# R7FA6M5BH register map
Vendor: Renesas Electronics Corporation; Series: RA6; File version: 1.20.01
CPU: CM33 r0p4, little endian, MPU, FPU, VTOR, 4 interrupt priority bits, 96 interrupts
Registers are 32-bit, read-write, reset 0x0 unless marked. A register's access mark holds for its fields unless they carry their own. Offsets are from the block's base; [hi:lo] are bit positions; {n}, {i} and the like mark numbered series; 'fields as' and 'values as' point back to an identical list.

## PFS — Control Register
Base 0x40080800
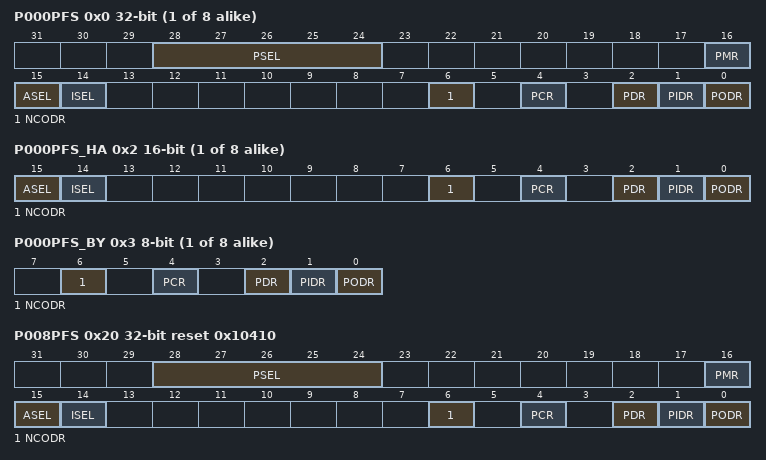
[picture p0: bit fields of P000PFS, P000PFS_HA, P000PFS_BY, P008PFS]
{0x0+4i} P00{i}PFS (i=0..7) (reset mask 0xFFFFFFFD) — Port 00{i} Pin Function Select Register
  [28:24] PSEL — Peripheral Select
  [16] PMR — Port Mode Control
    0=Use as general I/O pin; 1=Use as I/O port for peripheral functions
  [15] ASEL — Analog Input Enable
    0=Do not use as analog pin; 1=Use as analog pin
  [14] ISEL — IRQ Input Enable
    0=Do not use as IRQn input pin; 1=Use as IRQn input pin
  [6] NCODR — N-Channel Open-Drain Control
    0=Output CMOS; 1=Output NMOS open-drain
  [4] PCR — Pull-up Control
    0=Disable input pull-up; 1=Enable input pull-up
  [2] PDR — Port Direction
    0=Input (functions as an input pin); 1=Output (functions as an output pin)
  [1] PIDR ro — Port State
    0=Low level; 1=High level
  [0] PODR — Port Output Data
    0=Output low; 1=Output high
{0x2+4i} P00{i}PFS_HA (i=0..7) 16-bit (reset mask 0xFFFD) (alternate view of P00{i}PFS) — Port 00{i} Pin Function Select Register
  [15] ASEL — Analog Input Enable
    0=Do not use as analog pin; 1=Use as analog pin
  [14] ISEL — IRQ Input Enable
    0=Do not use as IRQn input pin; 1=Use as IRQn input pin
  [6] NCODR — N-Channel Open-Drain Control
    0=Output CMOS; 1=Output NMOS open-drain
  [4] PCR — Pull-up Control
    0=Disable input pull-up; 1=Enable input pull-up
  [2] PDR — Port Direction
    values as P000PFS.PDR
  [1] PIDR ro — Port State
    0=Low level; 1=High level
  [0] PODR — Port Output Data
    0=Output low; 1=Output high
{0x3+4i} P00{i}PFS_BY (i=0..7) 8-bit (reset mask 0xFD) (alternate view of P00{i}PFS) — Port 00{i} Pin Function Select Register
  [6] NCODR — N-Channel Open-Drain Control
    0=Output CMOS; 1=Output NMOS open-drain
  [4] PCR — Pull-up Control
    0=Disable input pull-up; 1=Enable input pull-up
  [2] PDR — Port Direction
    values as P000PFS.PDR
  [1] PIDR ro — Port State
    0=Low level; 1=High level
  [0] PODR — Port Output Data
    0=Output low; 1=Output high
0x20 P008PFS reset 0x10410 (reset mask 0xFFFFFFFD) — Port 008 Pin Function Select Register
  fields as P000PFS
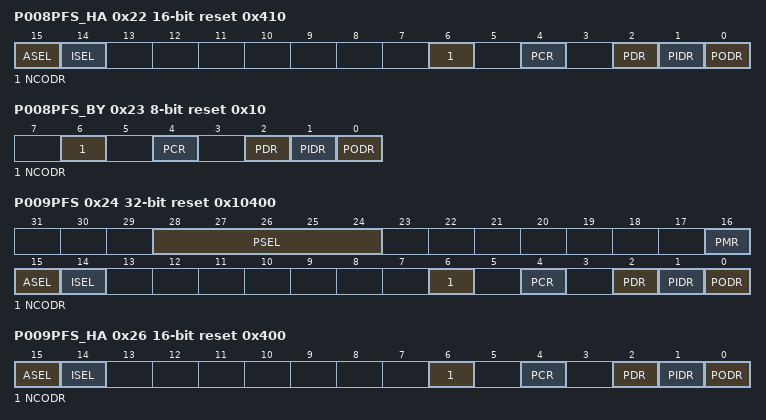
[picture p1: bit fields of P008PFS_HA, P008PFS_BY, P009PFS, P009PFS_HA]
0x22 P008PFS_HA 16-bit reset 0x410 (reset mask 0xFFFD) (alternate view of P008PFS) — Port 008 Pin Function Select Register
  fields as P000PFS_HA
0x23 P008PFS_BY 8-bit reset 0x10 (reset mask 0xFD) (alternate view of P008PFS) — Port 008 Pin Function Select Register
  fields as P000PFS_BY
0x24 P009PFS reset 0x10400 (reset mask 0xFFFFFFFD) — Port 009 Pin Function Select Register
  fields as P000PFS
0x26 P009PFS_HA 16-bit reset 0x400 (reset mask 0xFFFD) (alternate view of P009PFS) — Port 009 Pin Function Select Register
  fields as P000PFS_HA
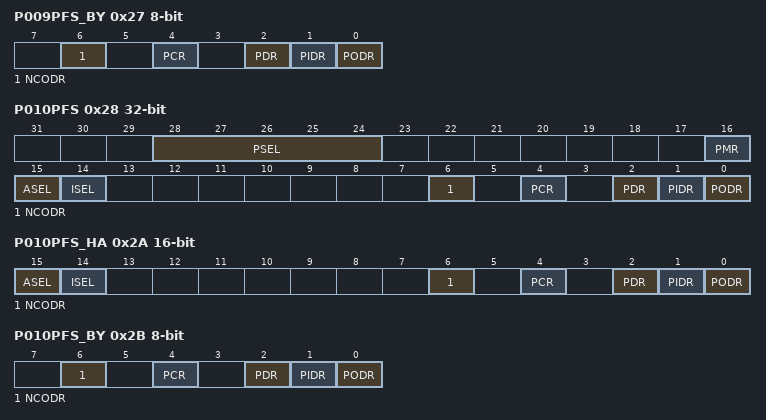
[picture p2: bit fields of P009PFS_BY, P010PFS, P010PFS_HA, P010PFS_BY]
0x27 P009PFS_BY 8-bit (reset mask 0xFD) (alternate view of P009PFS) — Port 009 Pin Function Select Register
  fields as P000PFS_BY
0x28 P010PFS (reset mask 0xFFFFFFFD) — Port 010 Pin Function Select Register
  fields as P000PFS
0x2A P010PFS_HA 16-bit (reset mask 0xFFFD) (alternate view of P010PFS) — Port 010 Pin Function Select Register
  fields as P000PFS_HA
0x2B P010PFS_BY 8-bit (reset mask 0xFD) (alternate view of P010PFS) — Port 010 Pin Function Select Register
  fields as P000PFS_BY
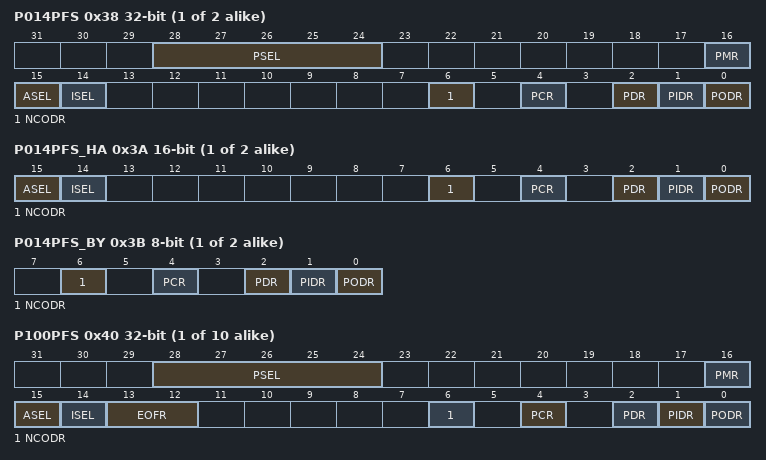
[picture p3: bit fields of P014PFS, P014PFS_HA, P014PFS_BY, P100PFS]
{0x0+4i} P0{i}PFS (i=14..15) (reset mask 0xFFFFFFFD) — Port 0{i} Pin Function Select Register
  fields as P000PFS
{0x2+4i} P0{i}PFS_HA (i=14..15) 16-bit (reset mask 0xFFFD) (alternate view of P0{i}PFS) — Port 0{i} Pin Function Select Register
  fields as P000PFS_HA
{0x3+4i} P0{i}PFS_BY (i=14..15) 8-bit (reset mask 0xFD) (alternate view of P0{i}PFS) — Port 0{i} Pin Function Select Register
  fields as P000PFS_BY
{0x40+4i} P10{i}PFS (i=0..9) (reset mask 0xFFFFFFFD) — Port 10{i} Pin Function Select Register
  [28:24] PSEL — Peripheral Select
  [16] PMR — Port Mode Control
    values as P000PFS.PMR
  [15] ASEL — Analog Input Enable
    0=Do not use as analog pin; 1=Use as analog pin
  [14] ISEL — IRQ Input Enable
    0=Do not use as IRQn input pin; 1=Use as IRQn input pin
  [13:12] EOFR — Event on Falling/Event on Rising
    0=Don't care; 1=Detect rising edge; 2=Detect falling edge; 3=Detect both edges
  [6] NCODR — N-Channel Open-Drain Control
    0=Output CMOS; 1=Output NMOS open-drain
  [4] PCR — Pull-up Control
    0=Disable input pull-up; 1=Enable input pull-up
  [2] PDR — Port Direction
    values as P000PFS.PDR
  [1] PIDR ro — Port State
    0=Low level; 1=High level
  [0] PODR — Port Output Data
    0=Output low; 1=Output high
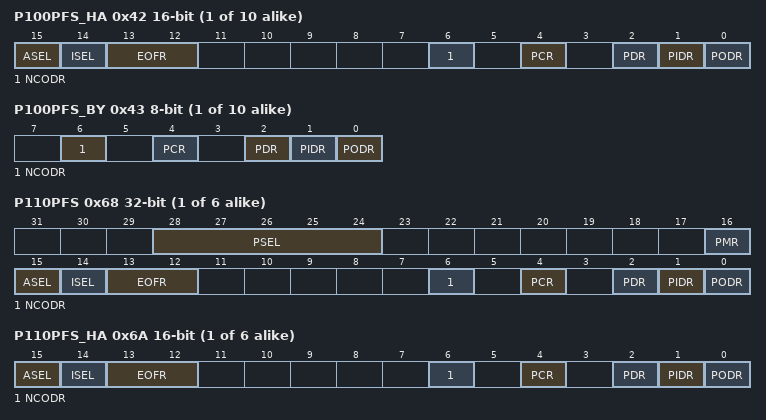
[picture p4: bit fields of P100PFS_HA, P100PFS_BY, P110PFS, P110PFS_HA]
{0x42+4i} P10{i}PFS_HA (i=0..9) 16-bit (reset mask 0xFFFD) (alternate view of P10{i}PFS) — Port 10{i} Pin Function Select Register
  [15] ASEL — Analog Input Enable
    0=Do not use as analog pin; 1=Use as analog pin
  [14] ISEL — IRQ Input Enable
    0=Do not use as IRQn input pin; 1=Use as IRQn input pin
  [13:12] EOFR — Event on Falling/Event on Rising
    values as P100PFS.EOFR
  [6] NCODR — N-Channel Open-Drain Control
    0=Output CMOS; 1=Output NMOS open-drain
  [4] PCR — Pull-up Control
    0=Disable input pull-up; 1=Enable input pull-up
  [2] PDR — Port Direction
    values as P000PFS.PDR
  [1] PIDR ro — Port State
    0=Low level; 1=High level
  [0] PODR — Port Output Data
    0=Output low; 1=Output high
{0x43+4i} P10{i}PFS_BY (i=0..9) 8-bit (reset mask 0xFD) (alternate view of P10{i}PFS) — Port 10{i} Pin Function Select Register
  fields as P000PFS_BY
{0x40+4i} P1{i}PFS (i=10..15) (reset mask 0xFFFFFFFD) — Port 1{i} Pin Function Select Register
  fields as P100PFS
{0x42+4i} P1{i}PFS_HA (i=10..15) 16-bit (reset mask 0xFFFD) (alternate view of P1{i}PFS) — Port 1{i} Pin Function Select Register
  fields as P100PFS_HA
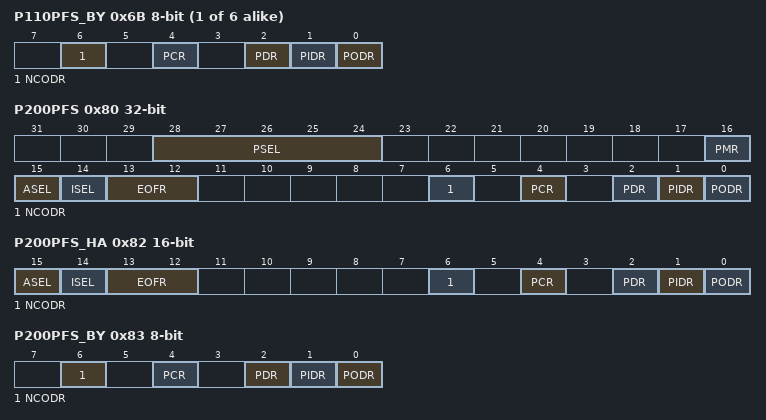
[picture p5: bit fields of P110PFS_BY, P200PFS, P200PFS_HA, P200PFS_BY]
{0x43+4i} P1{i}PFS_BY (i=10..15) 8-bit (reset mask 0xFD) (alternate view of P1{i}PFS) — Port 1{i} Pin Function Select Register
  fields as P000PFS_BY
0x80 P200PFS (reset mask 0xFFFFFFFD) — Port 200 Pin Function Select Register
  fields as P100PFS
0x82 P200PFS_HA 16-bit (reset mask 0xFFFD) (alternate view of P200PFS) — Port 200 Pin Function Select Register
  fields as P100PFS_HA
0x83 P200PFS_BY 8-bit (reset mask 0xFD) (alternate view of P200PFS) — Port 200 Pin Function Select Register
  fields as P000PFS_BY
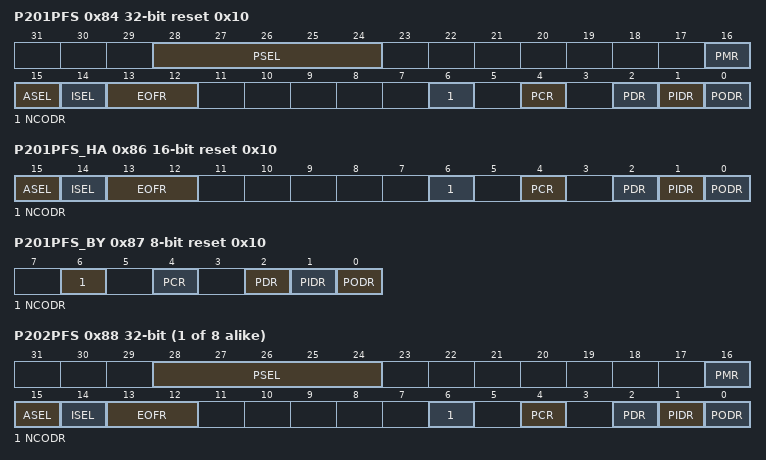
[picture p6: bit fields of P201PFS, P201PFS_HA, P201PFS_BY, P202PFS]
0x84 P201PFS reset 0x10 (reset mask 0xFFFFFFFD) — Port 201 Pin Function Select Register
  fields as P100PFS
0x86 P201PFS_HA 16-bit reset 0x10 (reset mask 0xFFFD) (alternate view of P201PFS) — Port 201 Pin Function Select Register
  fields as P100PFS_HA
0x87 P201PFS_BY 8-bit reset 0x10 (reset mask 0xFD) (alternate view of P201PFS) — Port 201 Pin Function Select Register
  fields as P000PFS_BY
{0x80+4i} P20{i}PFS (i=2..9) (reset mask 0xFFFFFFFD) — Port 20{i} Pin Function Select Register
  fields as P100PFS
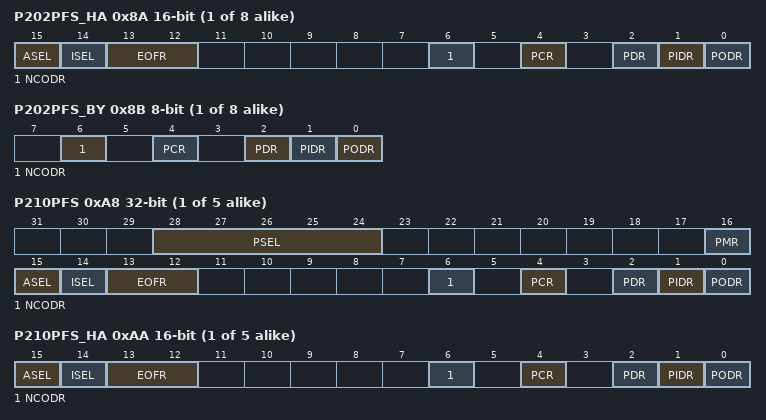
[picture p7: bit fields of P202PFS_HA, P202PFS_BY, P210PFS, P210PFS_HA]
{0x82+4i} P20{i}PFS_HA (i=2..9) 16-bit (reset mask 0xFFFD) (alternate view of P20{i}PFS) — Port 20{i} Pin Function Select Register
  fields as P100PFS_HA
{0x83+4i} P20{i}PFS_BY (i=2..9) 8-bit (reset mask 0xFD) (alternate view of P20{i}PFS) — Port 20{i} Pin Function Select Register
  fields as P000PFS_BY
{0x80+4i} P2{i}PFS (i=10..14) (reset mask 0xFFFFFFFD) — Port 2{i} Pin Function Select Register
  fields as P100PFS
{0x82+4i} P2{i}PFS_HA (i=10..14) 16-bit (reset mask 0xFFFD) (alternate view of P2{i}PFS) — Port 2{i} Pin Function Select Register
  fields as P100PFS_HA
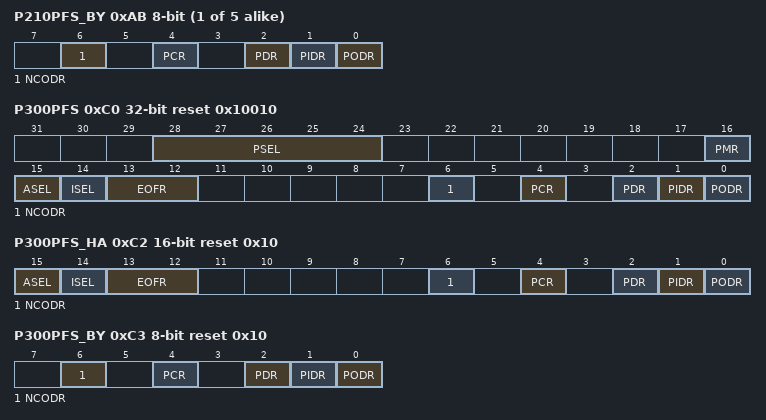
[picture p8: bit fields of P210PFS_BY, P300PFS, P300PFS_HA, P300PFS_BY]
{0x83+4i} P2{i}PFS_BY (i=10..14) 8-bit (reset mask 0xFD) (alternate view of P2{i}PFS) — Port 2{i} Pin Function Select Register
  fields as P000PFS_BY
0xC0 P300PFS reset 0x10010 (reset mask 0xFFFFFFFD) — Port 300 Pin Function Select Register
  fields as P100PFS
0xC2 P300PFS_HA 16-bit reset 0x10 (reset mask 0xFFFD) (alternate view of P300PFS) — Port 300 Pin Function Select Register
  fields as P100PFS_HA
0xC3 P300PFS_BY 8-bit reset 0x10 (reset mask 0xFD) (alternate view of P300PFS) — Port 300 Pin Function Select Register
  fields as P000PFS_BY
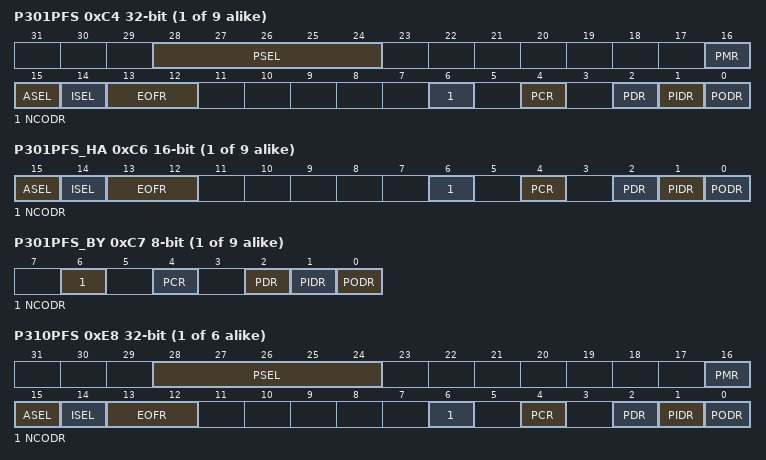
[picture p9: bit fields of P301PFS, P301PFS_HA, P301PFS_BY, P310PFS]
{0xC0+4i} P30{i}PFS (i=1..9) (reset mask 0xFFFFFFFD) — Port 30{i} Pin Function Select Register
  fields as P100PFS
{0xC2+4i} P30{i}PFS_HA (i=1..9) 16-bit (reset mask 0xFFFD) (alternate view of P30{i}PFS) — Port 30{i} Pin Function Select Register
  fields as P100PFS_HA
{0xC3+4i} P30{i}PFS_BY (i=1..9) 8-bit (reset mask 0xFD) (alternate view of P30{i}PFS) — Port 30{i} Pin Function Select Register
  fields as P000PFS_BY
{0xC0+4i} P3{i}PFS (i=10..15) (reset mask 0xFFFFFFFD) — Port 3{i} Pin Function Select Register
  fields as P100PFS
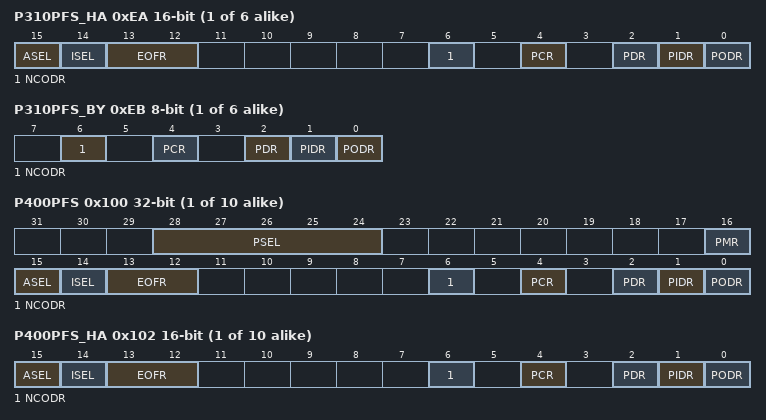
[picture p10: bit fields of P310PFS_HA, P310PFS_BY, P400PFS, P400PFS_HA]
{0xC2+4i} P3{i}PFS_HA (i=10..15) 16-bit (reset mask 0xFFFD) (alternate view of P3{i}PFS) — Port 3{i} Pin Function Select Register
  fields as P100PFS_HA
{0xC3+4i} P3{i}PFS_BY (i=10..15) 8-bit (reset mask 0xFD) (alternate view of P3{i}PFS) — Port 3{i} Pin Function Select Register
  fields as P000PFS_BY
{0x100+4i} P40{i}PFS (i=0..9) (reset mask 0xFFFFFFFD) — Port 40{i} Pin Function Select Register
  fields as P100PFS
{0x102+4i} P40{i}PFS_HA (i=0..9) 16-bit (reset mask 0xFFFD) (alternate view of P40{i}PFS) — Port 40{i} Pin Function Select Register
  fields as P100PFS_HA
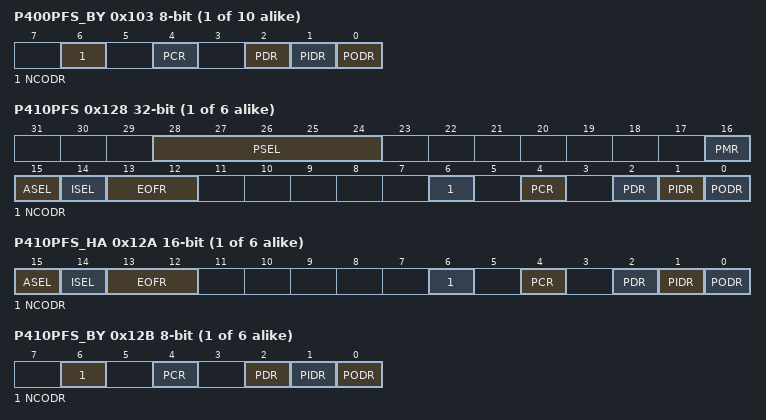
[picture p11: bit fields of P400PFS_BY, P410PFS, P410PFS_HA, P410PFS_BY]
{0x103+4i} P40{i}PFS_BY (i=0..9) 8-bit (reset mask 0xFD) (alternate view of P40{i}PFS) — Port 40{i} Pin Function Select Register
  fields as P000PFS_BY
{0x100+4i} P4{i}PFS (i=10..15) (reset mask 0xFFFFFFFD) — Port 4{i} Pin Function Select Register
  fields as P100PFS
{0x102+4i} P4{i}PFS_HA (i=10..15) 16-bit (reset mask 0xFFFD) (alternate view of P4{i}PFS) — Port 4{i} Pin Function Select Register
  fields as P100PFS_HA
{0x103+4i} P4{i}PFS_BY (i=10..15) 8-bit (reset mask 0xFD) (alternate view of P4{i}PFS) — Port 4{i} Pin Function Select Register
  fields as P000PFS_BY
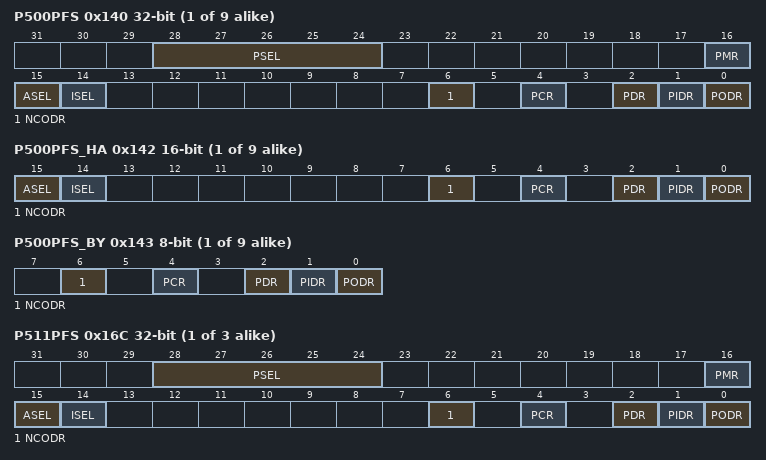
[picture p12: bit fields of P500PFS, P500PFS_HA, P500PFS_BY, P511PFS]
{0x140+4i} P50{i}PFS (i=0..8) (reset mask 0xFFFFFFFD) — Port 50{i} Pin Function Select Register
  fields as P000PFS
{0x142+4i} P50{i}PFS_HA (i=0..8) 16-bit (reset mask 0xFFFD) (alternate view of P50{i}PFS) — Port 50{i} Pin Function Select Register
  fields as P000PFS_HA
{0x143+4i} P50{i}PFS_BY (i=0..8) 8-bit (reset mask 0xFD) (alternate view of P50{i}PFS) — Port 50{i} Pin Function Select Register
  fields as P000PFS_BY
{0x140+4i} P5{i}PFS (i=11..13) (reset mask 0xFFFFFFFD) — Port 5{i} Pin Function Select Register
  fields as P000PFS
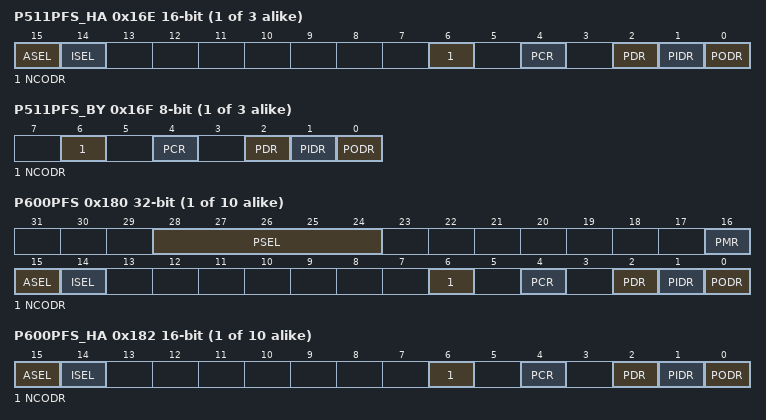
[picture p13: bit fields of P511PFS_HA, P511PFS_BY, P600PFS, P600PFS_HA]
{0x142+4i} P5{i}PFS_HA (i=11..13) 16-bit (reset mask 0xFFFD) (alternate view of P5{i}PFS) — Port 5{i} Pin Function Select Register
  fields as P000PFS_HA
{0x143+4i} P5{i}PFS_BY (i=11..13) 8-bit (reset mask 0xFD) (alternate view of P5{i}PFS) — Port 5{i} Pin Function Select Register
  fields as P000PFS_BY
{0x180+4i} P60{i}PFS (i=0..9) (reset mask 0xFFFFFFFD) — Port 60{i} Pin Function Select Register
  fields as P000PFS
{0x182+4i} P60{i}PFS_HA (i=0..9) 16-bit (reset mask 0xFFFD) (alternate view of P60{i}PFS) — Port 60{i} Pin Function Select Register
  fields as P000PFS_HA
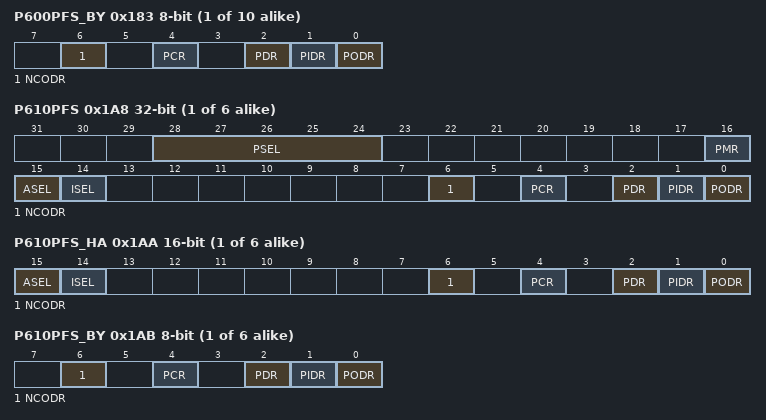
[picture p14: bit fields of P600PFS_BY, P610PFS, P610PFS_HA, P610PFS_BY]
{0x183+4i} P60{i}PFS_BY (i=0..9) 8-bit (reset mask 0xFD) (alternate view of P60{i}PFS) — Port 60{i} Pin Function Select Register
  fields as P000PFS_BY
{0x180+4i} P6{i}PFS (i=10..15) (reset mask 0xFFFFFFFD) — Port 6{i} Pin Function Select Register
  fields as P000PFS
{0x182+4i} P6{i}PFS_HA (i=10..15) 16-bit (reset mask 0xFFFD) (alternate view of P6{i}PFS) — Port 6{i} Pin Function Select Register
  fields as P000PFS_HA
{0x183+4i} P6{i}PFS_BY (i=10..15) 8-bit (reset mask 0xFD) (alternate view of P6{i}PFS) — Port 6{i} Pin Function Select Register
  fields as P000PFS_BY
{0x1C0+4i} P70{i}PFS (i=0..7) (reset mask 0xFFFFFFFD) — Port 70{i} Pin Function Select Register
  fields as P000PFS
{0x1C2+4i} P70{i}PFS_HA (i=0..7) 16-bit (reset mask 0xFFFD) (alternate view of P70{i}PFS) — Port 70{i} Pin Function Select Register
  fields as P000PFS_HA
{0x1C3+4i} P70{i}PFS_BY (i=0..7) 8-bit (reset mask 0xFD) (alternate view of P70{i}PFS) — Port 70{i} Pin Function Select Register
  fields as P000PFS_BY
{0x1C0+4i} P70{i}PFS (i=8..9) (reset mask 0xFFFFFFFD) — Port 70{i} Pin Function Select Register
  fields as P000PFS
{0x1C2+4i} P70{i}PFS_HA (i=8..9) 16-bit (reset mask 0xFFFD) (alternate view of P70{i}PFS) — Port 70{i} Pin Function Select Register
  fields as P000PFS_HA
{0x1C3+4i} P70{i}PFS_BY (i=8..9) 8-bit (reset mask 0xFD) (alternate view of P70{i}PFS) — Port 70{i} Pin Function Select Register
  fields as P000PFS_BY
{0x1C0+4i} P7{i}PFS (i=10..13) (reset mask 0xFFFFFFFD) — Port 7{i} Pin Function Select Register
  fields as P000PFS
{0x1C2+4i} P7{i}PFS_HA (i=10..13) 16-bit (reset mask 0xFFFD) (alternate view of P7{i}PFS) — Port 7{i} Pin Function Select Register
  fields as P000PFS_HA
{0x1C3+4i} P7{i}PFS_BY (i=10..13) 8-bit (reset mask 0xFD) (alternate view of P7{i}PFS) — Port 7{i} Pin Function Select Register
  fields as P000PFS_BY
{0x200+4i} P80{i}PFS (i=0..6) (reset mask 0xFFFFFFFD) — Port 80{i} Pin Function Select Register
  fields as P000PFS
{0x202+4i} P80{i}PFS_HA (i=0..6) 16-bit (reset mask 0xFFFD) (alternate view of P80{i}PFS) — Port 80{i} Pin Function Select Register
  fields as P000PFS_HA
{0x203+4i} P80{i}PFS_BY (i=0..6) 8-bit (reset mask 0xFD) (alternate view of P80{i}PFS) — Port 80{i} Pin Function Select Register
  fields as P000PFS_BY
{0x240+4i} P90{i}PFS (i=0..1) (reset mask 0xFFFFFFFD) — Port 90{i} Pin Function Select Register
  fields as P000PFS
{0x242+4i} P90{i}PFS_HA (i=0..1) 16-bit (reset mask 0xFFFD) (alternate view of P90{i}PFS) — Port 90{i} Pin Function Select Register
  fields as P000PFS_HA
{0x243+4i} P90{i}PFS_BY (i=0..1) 8-bit (reset mask 0xFD) (alternate view of P90{i}PFS) — Port 90{i} Pin Function Select Register
  fields as P000PFS_BY
{0x240+4i} P90{i}PFS (i=5..8) (reset mask 0xFFFFFFFD) — Port 90{i} Pin Function Select Register
  fields as P000PFS
{0x242+4i} P90{i}PFS_HA (i=5..8) 16-bit (reset mask 0xFFFD) (alternate view of P90{i}PFS) — Port 90{i} Pin Function Select Register
  fields as P000PFS_HA
{0x243+4i} P90{i}PFS_BY (i=5..8) 8-bit (reset mask 0xFD) (alternate view of P90{i}PFS) — Port 90{i} Pin Function Select Register
  fields as P000PFS_BY
{0x280+4i} PA0{i}PFS (i=0..1) (reset mask 0xFFFFFFFD) — Port A0{i} Pin Function Select Register
  fields as P000PFS
{0x282+4i} PA0{i}PFS_HA (i=0..1) 16-bit (reset mask 0xFFFD) (alternate view of PA0{i}PFS) — Port A0{i} Pin Function Select Register
  fields as P000PFS_HA
{0x283+4i} PA0{i}PFS_BY (i=0..1) 8-bit (reset mask 0xFD) (alternate view of PA0{i}PFS) — Port A0{i} Pin Function Select Register
  fields as P000PFS_BY
{0x280+4i} PA0{i}PFS (i=8..9) (reset mask 0xFFFFFFFD) — Port A0{i} Pin Function Select Register
  fields as P000PFS
{0x282+4i} PA0{i}PFS_HA (i=8..9) 16-bit (reset mask 0xFFFD) (alternate view of PA0{i}PFS) — Port A0{i} Pin Function Select Register
  fields as P000PFS_HA
{0x283+4i} PA0{i}PFS_BY (i=8..9) 8-bit (reset mask 0xFD) (alternate view of PA0{i}PFS) — Port A0{i} Pin Function Select Register
  fields as P000PFS_BY
0x2A8 PA10PFS (reset mask 0xFFFFFFFD) — Port A10 Pin Function Select Register
  fields as P000PFS
0x2AA PA10PFS_HA 16-bit (reset mask 0xFFFD) (alternate view of PA10PFS) — Port A10 Pin Function Select Register
  fields as P000PFS_HA
0x2AB PA10PFS_BY 8-bit (reset mask 0xFD) (alternate view of PA10PFS) — Port A10 Pin Function Select Register
  fields as P000PFS_BY
{0x2C0+4i} PB0{i}PFS (i=0..1) (reset mask 0xFFFFFFFD) — Port B0{i} Pin Function Select Register
  fields as P000PFS
{0x2C2+4i} PB0{i}PFS_HA (i=0..1) 16-bit (reset mask 0xFFFD) (alternate view of PB0{i}PFS) — Port B0{i} Pin Function Select Register
  fields as P000PFS_HA
{0x2C3+4i} PB0{i}PFS_BY (i=0..1) 8-bit (reset mask 0xFD) (alternate view of PB0{i}PFS) — Port B0{i} Pin Function Select Register
  fields as P000PFS_BY
0x500 PFENET 8-bit — Ethernet Control Register
  [4] PHYMODE0 — Ethernet Mode Setting ch0
    0=RMII mode (ETHERC channel 0); 1=MII mode (ETHERC channel 0)
0x503 PWPR 8-bit reset 0x80 — Write-Protect Register
  [7] B0WI — PFSWE Bit Write Disable
    0=Writing to the PFSWE bit is enabled; 1=Writing to the PFSWE bit is disabled
  [6] PFSWE — PmnPFS Register Write Enable
    0=Writing to the PmnPFS register is disabled; 1=Writing to the PmnPFS register is enabled
0x505 PWPRS 8-bit reset 0x80 — Write-Protect Register for Secure
  [7] B0WI — PFSWE Bit Write Disable
    0=Enable writes the PFSWE bit; 1=Disable writes to the PFSWE bit
  [6] PFSWE — PmnPFS Register Write Enable
    0=Disable writes to the PmnPFS register; 1=Enable writes to the PmnPFS register
{0x510+2i} P{i}SAR (i=0..9) 16-bit reset 0xFFFF — Port Security Attribution register
  [15:0] PMNSA — Pmn Security Attribution
    0=Secure; 1=Non Secure
0x524 P{x}SAR (x=A,B; step 0x2) 16-bit reset 0xFFFF — Port Security Attribution register
  [15:0] PMNSA — Pmn Security Attribution
    0=Secure; 1=Non Secure
